# ipro7 register map
Vendor: intelpro; Series: BTBLE
CPU: ipro7, little endian
Registers are 32-bit, read-write, reset 0x0 unless marked. A register's access mark holds for its fields unless they carry their own. Offsets are from the block's base; [hi:lo] are bit positions; {n}, {i} and the like mark numbered series.

## ISP
Base 0x30048000
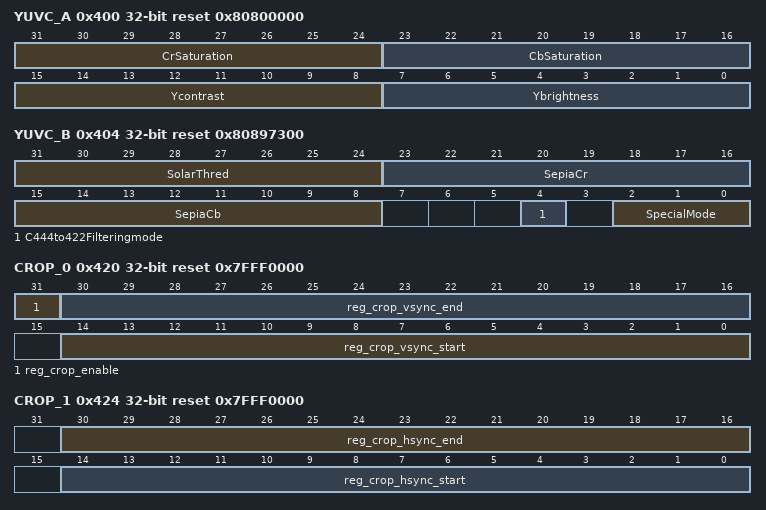
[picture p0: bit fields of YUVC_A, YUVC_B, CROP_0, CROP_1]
0x400 YUVC_A reset 0x80800000
  [31:24] CrSaturation — 0.0000000 ~1.1111111
  [23:16] CbSaturation — 0.0000000 ~1.1111111
  [15:8] Ycontrast — 0.0000000 ~1.1111111
  [7:0] Ybrightness — -128 ~ 127
0x404 YUVC_B reset 0x80897300
  [31:24] SolarThred — solarization threshold
  [23:16] SepiaCr
  [15:8] SepiaCb
  [4] C444to422Filteringmode — 0: LPF filtering, 1: No LPF filtering LPF is performed before 4:4:4 to 4:2:2 conversion.
  [2:0] SpecialMode — 0:normal, 1: sepia, 2: negative, 3: Y solarization 4: RGB solarization
0x420 CROP_0 reset 0x7FFF0000
  [31] reg_crop_enable — Enable signal
  [30:16] reg_crop_vsync_end — Crop vsync valid end
  [14:0] reg_crop_vsync_start — Crop vsync valid start
0x424 CROP_1 reset 0x7FFF0000
  [30:16] reg_crop_hsync_end — Crop hsync valid end
  [14:0] reg_crop_hsync_start — Crop hsync valid start
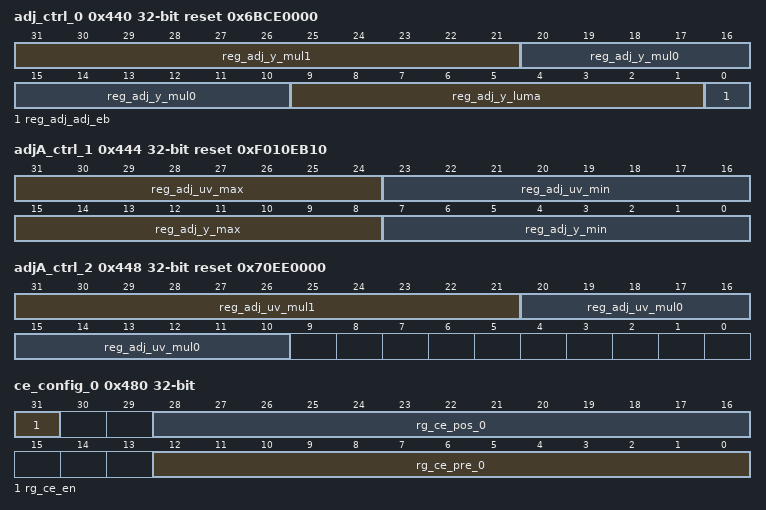
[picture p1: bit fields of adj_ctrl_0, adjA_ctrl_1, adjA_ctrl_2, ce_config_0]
0x440 adj_ctrl_0 reset 0x6BCE0000
  [31:21] reg_adj_y_mul1 — contrast adjust mul1
  [20:10] reg_adj_y_mul0 — contrast adjust mul0
  [9:1] reg_adj_y_luma — y_luma, higher luma, higher luma
  [0] reg_adj_adj_eb — enable limited range
0x444 adjA_ctrl_1 reset 0xF010EB10
  [31:24] reg_adj_uv_max — uv max clip value
  [23:16] reg_adj_uv_min — uv min clip value
  [15:8] reg_adj_y_max — y max clip value
  [7:0] reg_adj_y_min — y min clip value
0x448 adjA_ctrl_2 reset 0x70EE0000
  [31:21] reg_adj_uv_mul1 — saturation adjust, sw can multipiler gain to this vaue
  [20:10] reg_adj_uv_mul0 — saturation adjust, sw can multipiler gain to this vaue
0x480 ce_config_0
  [31] rg_ce_en — YUV2RGB_A Enable
  [28:16] rg_ce_pos_0 — YUV2RGB "post_offset_0" parameter
  [12:0] rg_ce_pre_0 — YUV2RGB "pre_offset_0" parameter
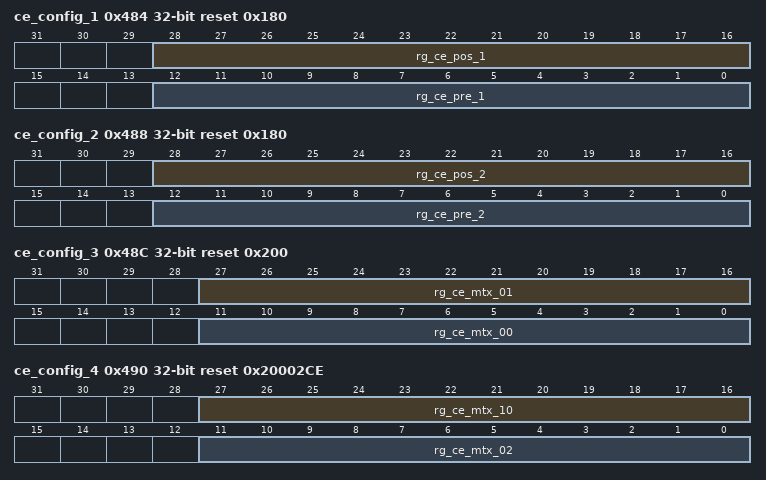
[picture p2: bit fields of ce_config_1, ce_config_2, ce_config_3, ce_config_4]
0x484 ce_config_1 reset 0x180
  [28:16] rg_ce_pos_1 — YUV2RGB "post_offset_1" parameter
  [12:0] rg_ce_pre_1 — YUV2RGB "pre_offset_1" parameter
0x488 ce_config_2 reset 0x180
  [28:16] rg_ce_pos_2 — YUV2RGB "post_offset_2" parameter
  [12:0] rg_ce_pre_2 — YUV2RGB "pre_offset_2" parameter
0x48C ce_config_3 reset 0x200
  [27:16] rg_ce_mtx_01 — YUV2RGB "matrix_01" parameter
  [11:0] rg_ce_mtx_00 — YUV2RGB "matrix_00" parameter
0x490 ce_config_4 reset 0x20002CE
  [27:16] rg_ce_mtx_10 — YUV2RGB "matrix_10" parameter
  [11:0] rg_ce_mtx_02 — YUV2RGB "matrix_02" parameter
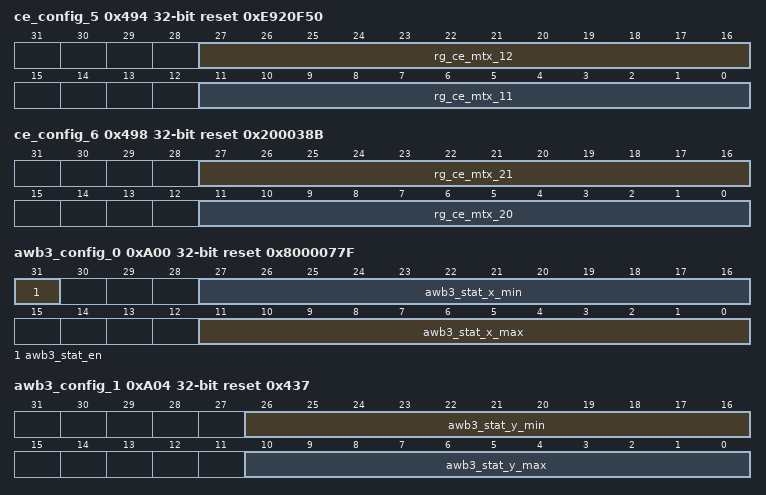
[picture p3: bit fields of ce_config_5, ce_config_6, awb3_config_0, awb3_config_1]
0x494 ce_config_5 reset 0xE920F50
  [27:16] rg_ce_mtx_12 — YUV2RGB "matrix_12" parameter
  [11:0] rg_ce_mtx_11 — YUV2RGB "matrix_11" parameter
0x498 ce_config_6 reset 0x200038B
  [27:16] rg_ce_mtx_21 — YUV2RGB "matrix_21" parameter
  [11:0] rg_ce_mtx_20 — YUV2RGB "matrix_20" parameter
0x49C ce_config_7
  [11:0] rg_ce_mtx_22 — YUV2RGB "matrix_22" parameter
0xA00 awb3_config_0 reset 0x8000077F
  [31] awb3_stat_en — 1: enable awb histogram, 0: disable awb histogram
  [27:16] awb3_stat_x_min — start pixel of awb histogram statistic, must be even number
  [11:0] awb3_stat_x_max — end pixel of awb histogram statistic, must be odd number
0xA04 awb3_config_1 reset 0x437
  [26:16] awb3_stat_y_min — start line of awb histogram statistic
  [10:0] awb3_stat_y_max — end line of awb histogram statistic
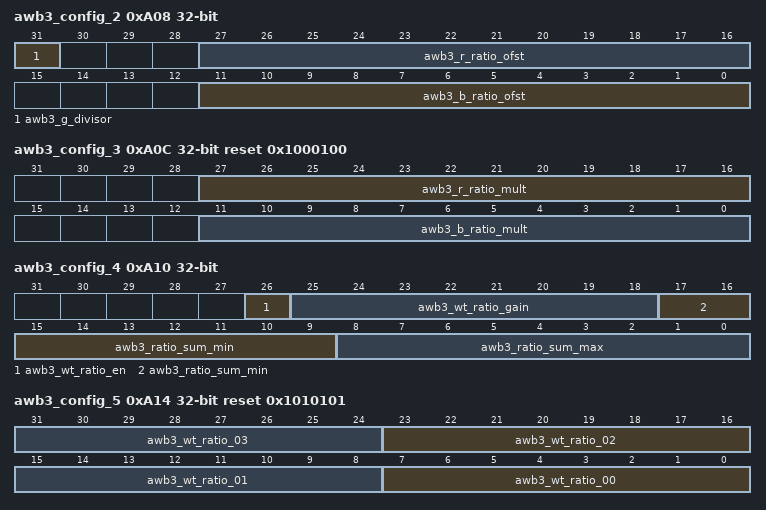
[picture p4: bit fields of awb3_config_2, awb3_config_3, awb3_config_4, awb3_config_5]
0xA08 awb3_config_2
  [31] awb3_g_divisor — 1: calculate R/G or B/G(noted as {R,G} ratio in the following), 0: calculate G/R or G/B (noted as {B,G} ratio in the following)
  [27:16] awb3_r_ratio_ofst — offset for {R,G}-ratio
  [11:0] awb3_b_ratio_ofst — offset for {B,G}-ratio
0xA0C awb3_config_3 reset 0x1000100
  [27:16] awb3_r_ratio_mult — {R,G}-ratio multiplier
  [11:0] awb3_b_ratio_mult — {B,G}-ratio multiplier
0xA10 awb3_config_4
  [26] awb3_wt_ratio_en — 1: enable adaptive weighting, 0: constant weighting for ratio calculation
  [25:18] awb3_wt_ratio_gain — gain of weighted ratio
  [17:9] awb3_ratio_sum_min — lower bound of total ratio for hexagon statistics
  [8:0] awb3_ratio_sum_max — upper bound of total ratio for hexagon statistics
0xA14 awb3_config_5 reset 0x1010101
  [8n+7:8n] awb3_wt_ratio_{n:02} (n=0..3) — coefficient for adaptive ratio weight
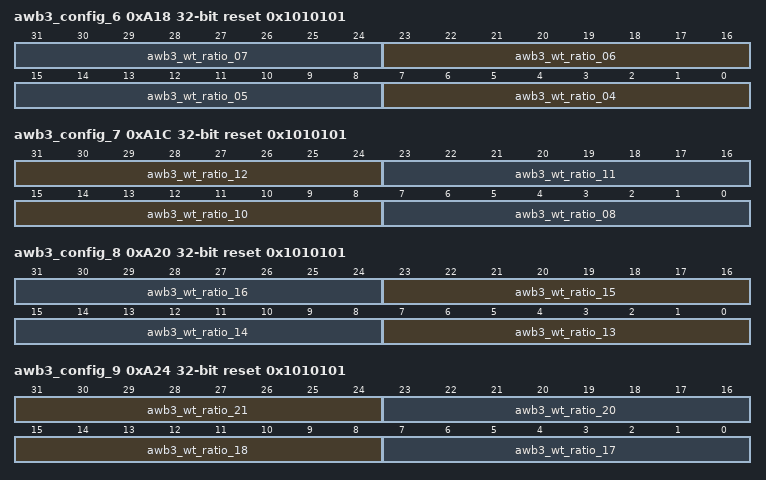
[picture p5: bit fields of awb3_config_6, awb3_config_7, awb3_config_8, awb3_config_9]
0xA18 awb3_config_6 reset 0x1010101
  [8n-25:8n-32] awb3_wt_ratio_{n:02} (n=4..7) — coefficient for adaptive ratio weight
0xA1C awb3_config_7 reset 0x1010101
  [31:24] awb3_wt_ratio_12 — coefficient for adaptive ratio weight
  [23:16] awb3_wt_ratio_11 — coefficient for adaptive ratio weight
  [15:8] awb3_wt_ratio_10 — coefficient for adaptive ratio weight
  [7:0] awb3_wt_ratio_08 — coefficient for adaptive ratio weight
0xA20 awb3_config_8 reset 0x1010101
  [8n-97:8n-104] awb3_wt_ratio_{n} (n=13..16) — coefficient for adaptive ratio weight
0xA24 awb3_config_9 reset 0x1010101
  [31:24] awb3_wt_ratio_21 — coefficient for adaptive ratio weight
  [23:16] awb3_wt_ratio_20 — coefficient for adaptive ratio weight
  [15:8] awb3_wt_ratio_18 — coefficient for adaptive ratio weight
  [7:0] awb3_wt_ratio_17 — coefficient for adaptive ratio weight
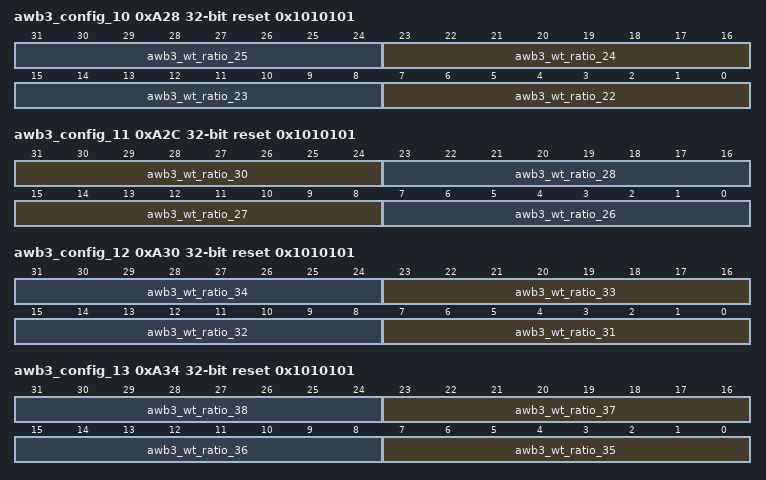
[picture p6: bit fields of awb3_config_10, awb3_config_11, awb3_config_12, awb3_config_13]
0xA28 awb3_config_10 reset 0x1010101
  [8n-169:8n-176] awb3_wt_ratio_{n} (n=22..25) — coefficient for adaptive ratio weight
0xA2C awb3_config_11 reset 0x1010101
  [31:24] awb3_wt_ratio_30 — coefficient for adaptive ratio weight
  [23:16] awb3_wt_ratio_28 — coefficient for adaptive ratio weight
  [15:8] awb3_wt_ratio_27 — coefficient for adaptive ratio weight
  [7:0] awb3_wt_ratio_26 — coefficient for adaptive ratio weight
0xA30 awb3_config_12 reset 0x1010101
  [8n-241:8n-248] awb3_wt_ratio_{n} (n=31..34) — coefficient for adaptive ratio weight
0xA34 awb3_config_13 reset 0x1010101
  [8n-273:8n-280] awb3_wt_ratio_{n} (n=35..38) — coefficient for adaptive ratio weight
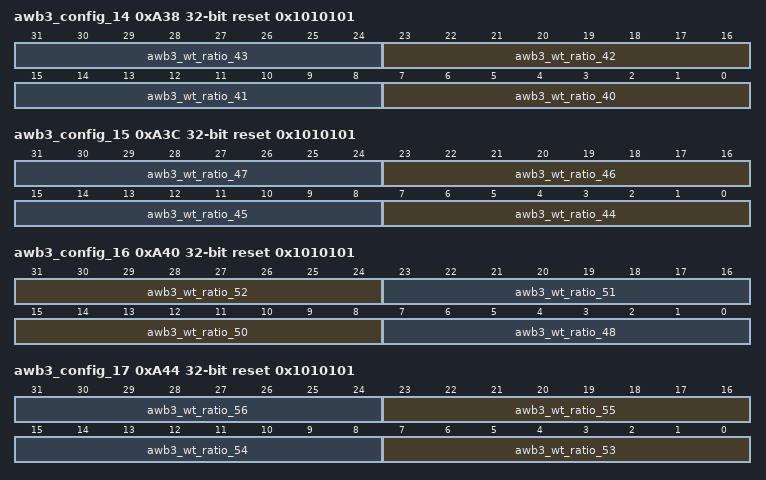
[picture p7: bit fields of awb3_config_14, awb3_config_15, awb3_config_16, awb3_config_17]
0xA38 awb3_config_14 reset 0x1010101
  [8n-313:8n-320] awb3_wt_ratio_{n} (n=40..43) — coefficient for adaptive ratio weight
0xA3C awb3_config_15 reset 0x1010101
  [8n-345:8n-352] awb3_wt_ratio_{n} (n=44..47) — coefficient for adaptive ratio weight
0xA40 awb3_config_16 reset 0x1010101
  [31:24] awb3_wt_ratio_52 — coefficient for adaptive ratio weight
  [23:16] awb3_wt_ratio_51 — coefficient for adaptive ratio weight
  [15:8] awb3_wt_ratio_50 — coefficient for adaptive ratio weight
  [7:0] awb3_wt_ratio_48 — coefficient for adaptive ratio weight
0xA44 awb3_config_17 reset 0x1010101
  [8n-417:8n-424] awb3_wt_ratio_{n} (n=53..56) — coefficient for adaptive ratio weight
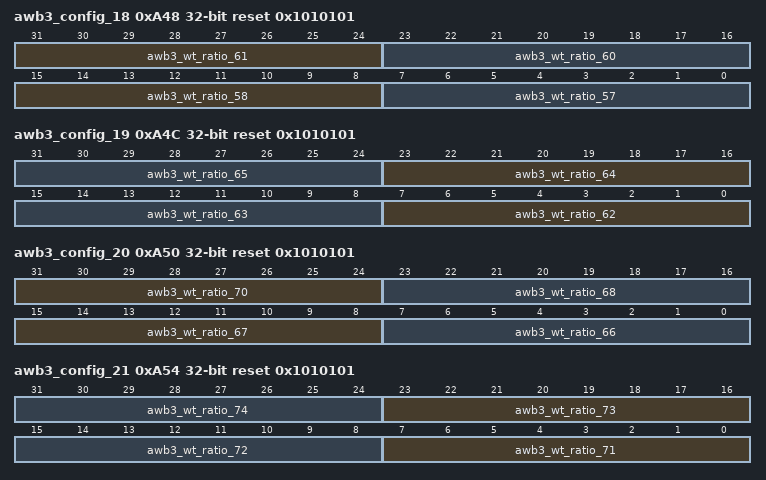
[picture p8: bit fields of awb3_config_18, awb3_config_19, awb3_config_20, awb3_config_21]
0xA48 awb3_config_18 reset 0x1010101
  [31:24] awb3_wt_ratio_61 — coefficient for adaptive ratio weight
  [23:16] awb3_wt_ratio_60 — coefficient for adaptive ratio weight
  [15:8] awb3_wt_ratio_58 — coefficient for adaptive ratio weight
  [7:0] awb3_wt_ratio_57 — coefficient for adaptive ratio weight
0xA4C awb3_config_19 reset 0x1010101
  [8n-489:8n-496] awb3_wt_ratio_{n} (n=62..65) — coefficient for adaptive ratio weight
0xA50 awb3_config_20 reset 0x1010101
  [31:24] awb3_wt_ratio_70 — coefficient for adaptive ratio weight
  [23:16] awb3_wt_ratio_68 — coefficient for adaptive ratio weight
  [15:8] awb3_wt_ratio_67 — coefficient for adaptive ratio weight
  [7:0] awb3_wt_ratio_66 — coefficient for adaptive ratio weight
0xA54 awb3_config_21 reset 0x1010101
  [8n-561:8n-568] awb3_wt_ratio_{n} (n=71..74) — coefficient for adaptive ratio weight
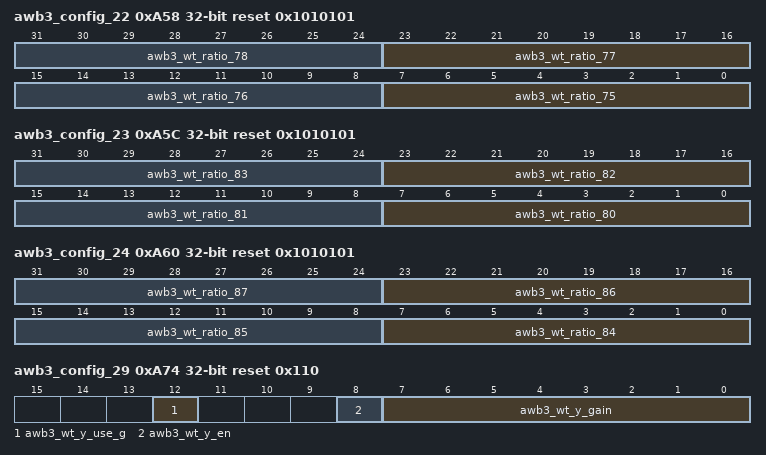
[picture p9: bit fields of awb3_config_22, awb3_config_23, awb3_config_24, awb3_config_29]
0xA58 awb3_config_22 reset 0x1010101
  [8n-593:8n-600] awb3_wt_ratio_{n} (n=75..78) — coefficient for adaptive ratio weight
0xA5C awb3_config_23 reset 0x1010101
  [8n-633:8n-640] awb3_wt_ratio_{n} (n=80..83) — coefficient for adaptive ratio weight
0xA60 awb3_config_24 reset 0x1010101
  [8n-665:8n-672] awb3_wt_ratio_{n} (n=84..87) — coefficient for adaptive ratio weight
0xA64 awb3_config_25 reset 0x1
  [7:0] awb3_wt_ratio_88 — coefficient for adaptive ratio weight
0xA68 awb3_config_26 reset 0x4D
  [11:0] awb3_y_r_coeff — R-coefficient of RGB to Y
0xA6C awb3_config_27 reset 0x96
  [11:0] awb3_y_g_coeff — G-coefficient of RGB to Y
0xA70 awb3_config_28 reset 0x1D
  [11:0] awb3_y_b_coeff — B-coefficient of RGB to Y
0xA74 awb3_config_29 reset 0x110
  [12] awb3_wt_y_use_g — 1: use G for luminant weight, 0: use Y for luminant weight
  [8] awb3_wt_y_en — 1: enable luminant weight statistic
  [7:0] awb3_wt_y_gain — luminance gain for weighted ratio
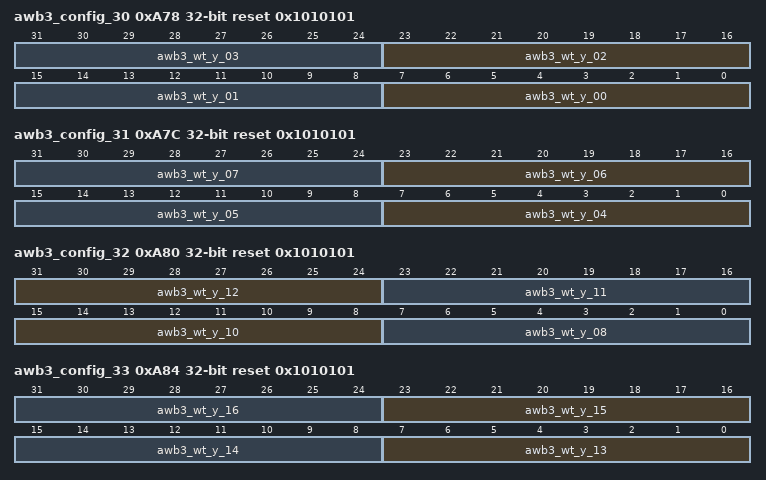
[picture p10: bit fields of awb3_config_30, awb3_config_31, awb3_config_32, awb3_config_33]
0xA78 awb3_config_30 reset 0x1010101
  [8n+7:8n] awb3_wt_y_{n:02} (n=0..3) — coefficient for adaptive luminant weight
0xA7C awb3_config_31 reset 0x1010101
  [8n-25:8n-32] awb3_wt_y_{n:02} (n=4..7) — coefficient for adaptive luminant weight
0xA80 awb3_config_32 reset 0x1010101
  [31:24] awb3_wt_y_12 — coefficient for adaptive luminant weight
  [23:16] awb3_wt_y_11 — coefficient for adaptive luminant weight
  [15:8] awb3_wt_y_10 — coefficient for adaptive luminant weight
  [7:0] awb3_wt_y_08 — coefficient for adaptive luminant weight
0xA84 awb3_config_33 reset 0x1010101
  [8n-97:8n-104] awb3_wt_y_{n} (n=13..16) — coefficient for adaptive luminant weight
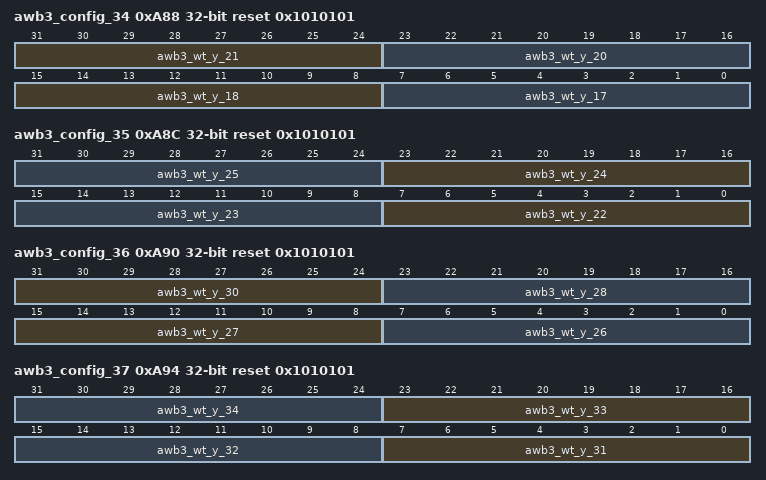
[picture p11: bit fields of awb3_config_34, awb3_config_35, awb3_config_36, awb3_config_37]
0xA88 awb3_config_34 reset 0x1010101
  [31:24] awb3_wt_y_21 — coefficient for adaptive luminant weight
  [23:16] awb3_wt_y_20 — coefficient for adaptive luminant weight
  [15:8] awb3_wt_y_18 — coefficient for adaptive luminant weight
  [7:0] awb3_wt_y_17 — coefficient for adaptive luminant weight
0xA8C awb3_config_35 reset 0x1010101
  [8n-169:8n-176] awb3_wt_y_{n} (n=22..25) — coefficient for adaptive luminant weight
0xA90 awb3_config_36 reset 0x1010101
  [31:24] awb3_wt_y_30 — coefficient for adaptive luminant weight
  [23:16] awb3_wt_y_28 — coefficient for adaptive luminant weight
  [15:8] awb3_wt_y_27 — coefficient for adaptive luminant weight
  [7:0] awb3_wt_y_26 — coefficient for adaptive luminant weight
0xA94 awb3_config_37 reset 0x1010101
  [8n-241:8n-248] awb3_wt_y_{n} (n=31..34) — coefficient for adaptive luminant weight
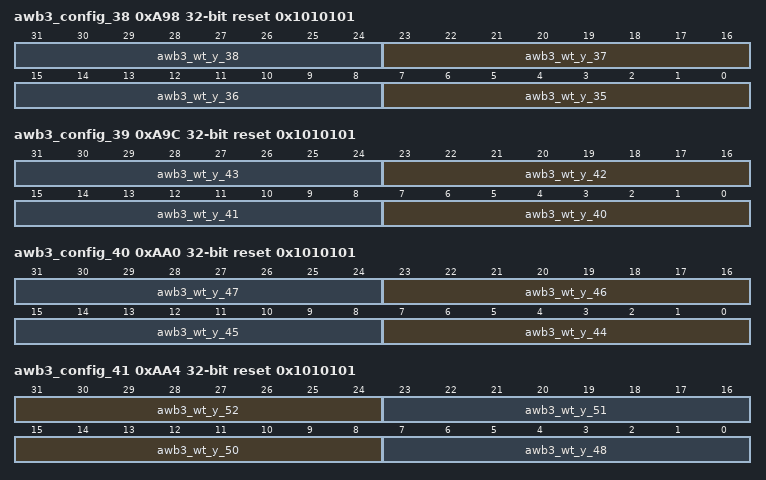
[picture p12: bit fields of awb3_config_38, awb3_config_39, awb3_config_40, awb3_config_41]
0xA98 awb3_config_38 reset 0x1010101
  [8n-273:8n-280] awb3_wt_y_{n} (n=35..38) — coefficient for adaptive luminant weight
0xA9C awb3_config_39 reset 0x1010101
  [8n-313:8n-320] awb3_wt_y_{n} (n=40..43) — coefficient for adaptive luminant weight
0xAA0 awb3_config_40 reset 0x1010101
  [8n-345:8n-352] awb3_wt_y_{n} (n=44..47) — coefficient for adaptive luminant weight
0xAA4 awb3_config_41 reset 0x1010101
  [31:24] awb3_wt_y_52 — coefficient for adaptive luminant weight
  [23:16] awb3_wt_y_51 — coefficient for adaptive luminant weight
  [15:8] awb3_wt_y_50 — coefficient for adaptive luminant weight
  [7:0] awb3_wt_y_48 — coefficient for adaptive luminant weight
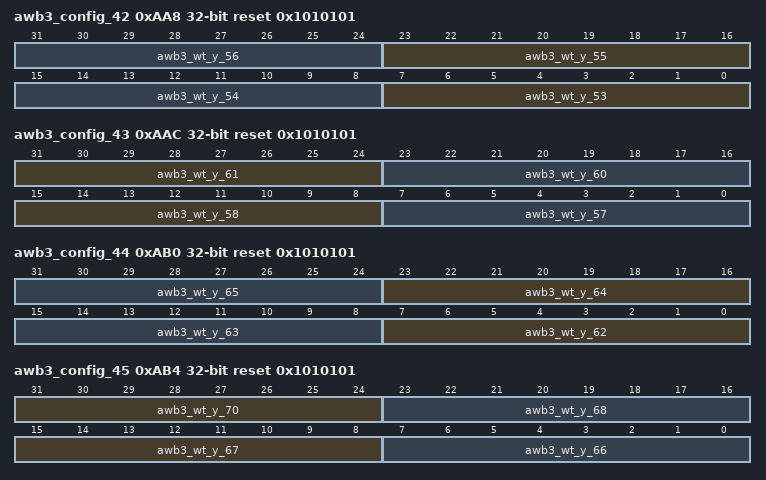
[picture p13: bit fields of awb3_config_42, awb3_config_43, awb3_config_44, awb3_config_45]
0xAA8 awb3_config_42 reset 0x1010101
  [8n-417:8n-424] awb3_wt_y_{n} (n=53..56) — coefficient for adaptive luminant weight
0xAAC awb3_config_43 reset 0x1010101
  [31:24] awb3_wt_y_61 — coefficient for adaptive luminant weight
  [23:16] awb3_wt_y_60 — coefficient for adaptive luminant weight
  [15:8] awb3_wt_y_58 — coefficient for adaptive luminant weight
  [7:0] awb3_wt_y_57 — coefficient for adaptive luminant weight
0xAB0 awb3_config_44 reset 0x1010101
  [8n-489:8n-496] awb3_wt_y_{n} (n=62..65) — coefficient for adaptive luminant weight
0xAB4 awb3_config_45 reset 0x1010101
  [31:24] awb3_wt_y_70 — coefficient for adaptive luminant weight
  [23:16] awb3_wt_y_68 — coefficient for adaptive luminant weight
  [15:8] awb3_wt_y_67 — coefficient for adaptive luminant weight
  [7:0] awb3_wt_y_66 — coefficient for adaptive luminant weight
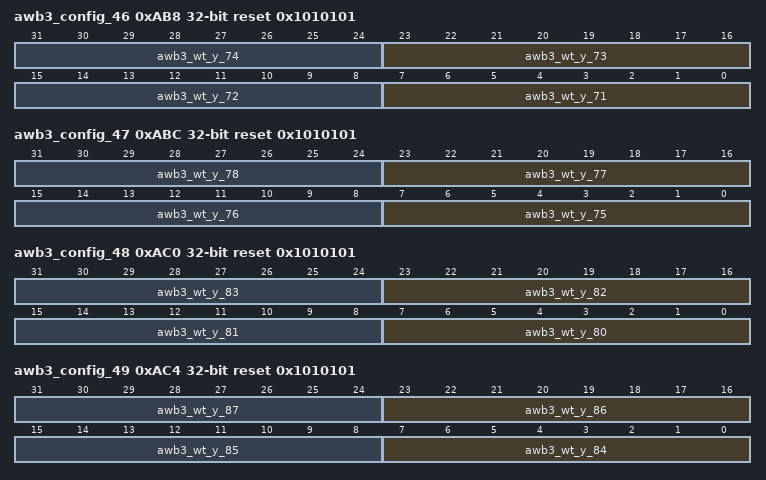
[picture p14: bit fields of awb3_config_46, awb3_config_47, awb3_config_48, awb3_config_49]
0xAB8 awb3_config_46 reset 0x1010101
  [8n-561:8n-568] awb3_wt_y_{n} (n=71..74) — coefficient for adaptive luminant weight
0xABC awb3_config_47 reset 0x1010101
  [8n-593:8n-600] awb3_wt_y_{n} (n=75..78) — coefficient for adaptive luminant weight
0xAC0 awb3_config_48 reset 0x1010101
  [8n-633:8n-640] awb3_wt_y_{n} (n=80..83) — coefficient for adaptive luminant weight
0xAC4 awb3_config_49 reset 0x1010101
  [8n-665:8n-672] awb3_wt_y_{n} (n=84..87) — coefficient for adaptive luminant weight
0xAC8 awb3_config_50 reset 0x1
  [7:0] awb3_wt_y_88 — coefficient for adaptive luminant weight
0xACC awb3_config_51 reset 0x1
  [8] awb3_count_zero_wt — 1: calculate pixels with all luminant weight, 0: only calculate pixels with non-zero luminant weight
  [5:4] awb3_ink_type — 0: dump mixture of luminant and ratio weight, 1: dump ratio weight, 2/3: dump luminant weight
  [3:0] awb3_ink_gain — scaling of luminance/ratio weight in dumping
0xAD8 awb3_sta_1 reset not defined
  [31:0] awb3_r_sum0l_r ro — R summaiton in statistic region
0xAE0 awb3_sta_3 reset not defined
  [31:0] awb3_g_sum0l_r ro — G summaiton in statistic region
0xAE8 awb3_sta_5 reset not defined
  [31:0] awb3_b_sum0l_r ro — B summaiton in statistic region
0xAF0 awb3_sta_7 reset not defined
  [31:0] awb3_r_sum_hex0l_r ro — R summaiton of pixels with ratio in upper/lower bound in statistic region
0xAF8 awb3_sta_9 reset not defined
  [31:0] awb3_g_sum_hex0l_r ro — G summaiton of pixels with ratio in upper/lower bound in statistic region
0xB00 awb3_sta_11 reset not defined
  [31:0] awb3_b_sum_hex0l_r ro — B summaiton of pixels with ratio in upper/lower bound in statistic region
0xB04 awb3_sta_12 (reset mask 0xFFF00000)
  [19:0] awb3_pixel_hex0_r ro — number of pixels with ratio in upper/lower bound in statistic region
0xB08 awb3_sta_13 (reset mask 0xFFFFFF00)
  [7:0] awb3_r_ratio_hex_y0u_r ro — summation of weighted {R,G}-ratio(upper part, most significant 8 bits)
0xB0C awb3_sta_14 reset not defined
  [31:0] awb3_r_ratio_hex_y0l_r ro — summation of weighted {R,G}- ratio(lower part, least significant 32 bits)
0xB10 awb3_sta_15 (reset mask 0xFFFFFF00)
  [7:0] awb3_b_ratio_hex_y0u_r ro — summation of weighted {B,G}-ratio(upper part)
0xB14 awb3_sta_16 reset not defined
  [31:0] awb3_b_ratio_hex_y0l_r ro — summation of weighted {B,G}- ratio(lower part)
0xB18 awb3_sta_17 (reset mask 0xF0000000)
  [27:0] awb3_wt_hex_y0_r ro — summation of weighted brightness
0xB1C awb3_sta_18 (reset mask 0xFFF00000)
  [19:0] awb3_pixel_hex_y0_r ro — number of pixels with valid weighted brightness and ratio in upper/lower bound in statistic region
0xB20 awb3_sta_19 (reset mask 0xFFFFFF00)
  [7:0] awb3_r_ratio_grid0u_r ro — summation of {R,G}-ratio in histogram(upper part)
0xB24 awb3_sta_20 reset not defined
  [31:0] awb3_r_ratio_grid0l_r ro — summation of {R,G}-ratio in histogram(lower part)
0xB28 awb3_sta_21 (reset mask 0xFFFFFF00)
  [7:0] awb3_b_ratio_grid0u_r ro — summation of {B,G}-ratio in histogram(upper part)
0xB2C awb3_sta_22 reset not defined
  [31:0] awb3_b_ratio_grid0l_r ro — summation of {B,G}-ratio in histogram(lower part)
0xB30 awb3_sta_23 (reset mask 0xF0000000)
  [27:0] awb3_wt_grid0_r ro — summation of weighting in histogram
0xB34 awb3_sta_24 (reset mask 0xFFF00000)
  [19:0] awb3_pixel_grid0_r ro — summation of pixel count in histogram
0xB54 awb3_sta_32 reset not defined
  [31:0] awb3_r_sum1l_r ro — R summaiton in statistic region
0xB5C awb3_sta_34 reset not defined
  [31:0] awb3_g_sum1l_r ro — G summaiton in statistic region
0xB64 awb3_sta_36 reset not defined
  [31:0] awb3_b_sum1l_r ro — B summaiton in statistic region
0xB6C awb3_sta_38 reset not defined
  [31:0] awb3_r_sum_hex1l_r ro — R summaiton of pixels with ratio in upper/lower bound in statistic region
0xB74 awb3_sta_40 reset not defined
  [31:0] awb3_g_sum_hex1l_r ro — G summaiton of pixels with ratio in upper/lower bound in statistic region
0xB7C awb3_sta_42 reset not defined
  [31:0] awb3_b_sum_hex1l_r ro — B summaiton of pixels with ratio in upper/lower bound in statistic region
0xB80 awb3_sta_43 (reset mask 0xFFF00000)
  [19:0] awb3_pixel_hex1_r ro — number of pixels with ratio in upper/lower bound in statistic region
0xB84 awb3_sta_44 (reset mask 0xFFFFFF00)
  [7:0] awb3_r_ratio_hex_y1u_r ro — summation of weighted {R,G}-ratio(upper part, most significant 8 bits)
0xB88 awb3_sta_45 reset not defined
  [31:0] awb3_r_ratio_hex_y1l_r ro — summation of weighted {R,G}- ratio(lower part, least significant 32 bits)
0xB8C awb3_sta_46 (reset mask 0xFFFFFF00)
  [7:0] awb3_b_ratio_hex_y1u_r ro — summation of weighted {B,G}-ratio(upper part)
0xB90 awb3_sta_47 reset not defined
  [31:0] awb3_b_ratio_hex_y1l_r ro — summation of weighted {B,G}- ratio(lower part)
0xB94 awb3_sta_48 (reset mask 0xF0000000)
  [27:0] awb3_wt_hex_y1_r ro — summation of weighted brightness
0xB98 awb3_sta_49 (reset mask 0xFFF00000)
  [19:0] awb3_pixel_hex_y1_r ro — number of pixels with valid weighted brightness and ratio in upper/lower bound in statistic region
0xB9C awb3_sta_50 (reset mask 0xFFFFFF00)
  [7:0] awb3_r_ratio_grid1u_r ro — summation of {R,G}-ratio in histogram(upper part)
0xBA0 awb3_sta_51 reset not defined
  [31:0] awb3_r_ratio_grid1l_r ro — summation of {R,G}-ratio in histogram(lower part)
0xBA4 awb3_sta_52 (reset mask 0xFFFFFF00)
  [7:0] awb3_b_ratio_grid1u_r ro — summation of {B,G}-ratio in histogram(upper part)
0xBA8 awb3_sta_53 reset not defined
  [31:0] awb3_b_ratio_grid1l_r ro — summation of {B,G}-ratio in histogram(lower part)
0xBAC awb3_sta_54 (reset mask 0xF0000000)
  [27:0] awb3_wt_grid1_r ro — summation of weighting in histogram
0xBB0 awb3_sta_55 (reset mask 0xFFF00000)
  [19:0] awb3_pixel_grid1_r ro — summation of pixel count in histogram
0xBCC awb3_status_0 (reset mask 0xFFFFFEE0)
  [8] awb3_buf_idx_r ro — read buffer index
  [4:0] awb3_w_cnt_r ro — write count of AWB histogram
0xC30 bayer2rgb_0
  [1:0] cr_rgb2bayer_mode — 2'b00 - R first pixel 2'b01 - GR first pixel 2'b10 - GB first pixel 2'b11 - B first pixel
0xC40 ae_roi_x
  [27:16] ae_roi_width — roi width
  [11:0] ae_roi_start_x — roi starting X pixel index(count from 0)
0xC44 ae_roi_y
  [26:16] ae_roi_height — roi height
  [10:0] ae_roi_start_y — roi starting Y pixel index(count from 0)
0xC48 ae_image_size
  [26:16] ae_image_height — image height
  [11:0] ae_image_width — image width
0xC4C ae_grid_size reset 0xE000000
  [28] ae_hist_roi_en — 1: pixel in ae2_roi_x/y are included in histogram; 0: all pixels are included in histogram
  [27] ae_hist_mode — 1: Y histogram; 0: bayer histogram
  [26] ae_hist_en — 1: enable AE histogram
  [25] ae_switch_bank_en — 0:AE occupies only 1 bank of memory 1:AE occupies 2 banks of memory(switch for each image)
  [24] new_ae_sta_enable — BL AE module enable/disable switch
  [23:20] ae_grid_x_max — horizontal number of grid in roi(max=12)
  [19:16] ae_grid_y_max — vertical number of grid in roi(max =8)
  [15:8] ae_grid_height — grid height in pixel (max=255)
  [7:0] ae_grid_width — grid width in pixel (max=255)
0xC50 ae_coeff
  [23:16] ae_ysum_coeff_b — Coefficient for RGB to YUV
  [15:8] ae_ysum_coeff_g — Coefficient for RGB to YUV
  [7:0] ae_ysum_coeff_r — Coefficient for RGB to YUV
0xC54 ae2_roi_x
  [27:16] ae_hist_x_min — start pixel of ae histogram statistic
  [11:0] ae_hist_x_max — end pixel of ae histogram statistic
0xC58 ae2_roi_y
  [26:16] ae_hist_y_min — start line of ae histogram statistic
  [10:0] ae_hist_y_max — end line of ae histogram statistic
0xC5C ae_status (reset mask 0xFE0EFE0F)
  [24:20] blae_w_cnt_r ro — write buf index
  [16] blae_buf_idx_r ro — read buf index
  [8:4] ae_hist_w_cnt_r ro — write buf index
0xC60 ae_sta_dbg (reset mask 0x80000000)
  [30] ae_fifo_empty ro — fifo empty flag
  [29] ae_operation_done ro — operation done flag
  [28:25] ae_control_status ro — 1:idle, 2: wait sof, 4:frame processing, 8:wait finish when disable
  [24] ae_fifo_full ro — fifo full flag
  [23:17] ae_grid_cnt_max ro — total grid count
  [16] ae_sta_int_flag ro — interrup flag(toggle each image)
  [15:8] ae_write_data_cnt ro — bus data counter of BL AE module
  [7] ae_sta_done ro — BL AE module done flag
  [6:0] ae_grid_cnt ro — processed grid index
0xF00 isp_dbg_0
  [11:8] cr_ink1_sel — ISP Debug DVP selection
  [3:0] cr_ink0_sel
0xFF8 isp_misc_0
  [6] rg_awb3_int_mask, [5] rg_ae_hist_int_mask, [4] rg_ae_int_mask
0xFFC isp_cfg_0
  [6] rg_awb3_int_clr wo — AE hist interrupt clear
  [5] rg_ae_hist_int_clr wo — AE hist interrupt clear
  [4] rg_ae_int_clr wo — AE interrupt clear
  [0] cr_sw_shd wo — SW force shadow
